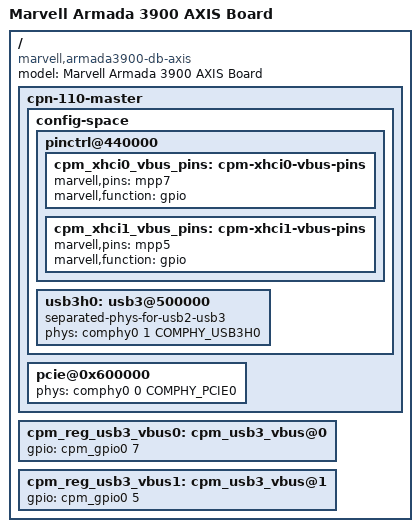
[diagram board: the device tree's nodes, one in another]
/*
 * Copyright (C) 2017 Marvell Technology Group Ltd.
 *
 * This file is dual-licensed: you can use it either under the terms
 * of the GPLv2 or the X11 license, at your option. Note that this dual
 * licensing only applies to this file, and not this project as a
 * whole.
 *
 *  a) This library is free software; you can redistribute it and/or
 *     modify it under the terms of the GNU General Public License as
 *     published by the Free Software Foundation; either version 2 of the
 *     License, or (at your option) any later version.
 *
 *     This library is distributed in the hope that it will be useful,
 *     but WITHOUT ANY WARRANTY; without even the implied warranty of
 *     MERCHANTABILITY or FITNESS FOR A PARTICULAR PURPOSE.  See the
 *     GNU General Public License for more details.
 *
 * Or, alternatively,
 *
 *  b) Permission is hereby granted, free of charge, to any person
 *     obtaining a copy of this software and associated documentation
 *     files (the "Software"), to deal in the Software without
 *     restriction, including without limitation the rights to use,
 *     copy, modify, merge, publish, distribute, sublicense, and/or
 *     sell copies of the Software, and to permit persons to whom the
 *     Software is furnished to do so, subject to the following
 *     conditions:
 *
 *     The above copyright notice and this permission notice shall be
 *     included in all copies or substantial portions of the Software.
 *
 *     THE SOFTWARE IS PROVIDED "AS IS", WITHOUT WARRANTY OF ANY KIND,
 *     EXPRESS OR IMPLIED, INCLUDING BUT NOT LIMITED TO THE WARRANTIES
 *     OF MERCHANTABILITY, FITNESS FOR A PARTICULAR PURPOSE AND
 *     NONINFRINGEMENT. IN NO EVENT SHALL THE AUTHORS OR COPYRIGHT
 *     HOLDERS BE LIABLE FOR ANY CLAIM, DAMAGES OR OTHER LIABILITY,
 *     WHETHER IN AN ACTION OF CONTRACT, TORT OR OTHERWISE, ARISING
 *     FROM, OUT OF OR IN CONNECTION WITH THE SOFTWARE OR THE USE OR
 *     OTHER DEALINGS IN THE SOFTWARE.
 */

#include "armada-3900-db.dtsi"

/ {
	model = "Marvell Armada 3900 AXIS Board";
	compatible = "marvell,armada3900-db-axis", "marvell,armada7040",
		     "marvell,armada-ap806-quad", "marvell,armada-ap806";

	cpn-110-master {
		config-space {
			pinctrl@440000 {
				cpm_xhci0_vbus_pins: cpm-xhci0-vbus-pins {
					marvell,pins = "mpp7";
					marvell,function = "gpio";
				};
				cpm_xhci1_vbus_pins: cpm-xhci1-vbus-pins {
					marvell,pins = "mpp5";
					marvell,function = "gpio";
				};
			};
			usb3h0: usb3@500000 {
				separated-phys-for-usb2-usb3;
				phys = <&comphy0 1 COMPHY_USB3H0>;
				phy-names = "usb3";
			};
		};

		pcie@0x600000 {
			phys = <&comphy0 0 COMPHY_PCIE0>;
			phy-names = "pcie-phy0";
		};
	};

	cpm_reg_usb3_vbus0: cpm_usb3_vbus@0 {
		gpio = <&cpm_gpio0 7 GPIO_ACTIVE_HIGH>;
	};
	cpm_reg_usb3_vbus1: cpm_usb3_vbus@1 {
		gpio = <&cpm_gpio0 5 GPIO_ACTIVE_HIGH>;
	};
};
